# TC80_VXX register map
Vendor: Geneal MCU Ltd.; Series: ARMCM0; File version: 1.2
CPU: CM0 r0p0, little endian, no MPU, no FPU, 2 interrupt priority bits
Registers are 32-bit, read-write, reset 0x0 unless marked. A register's access mark holds for its fields unless they carry their own. Offsets are from the block's base; [hi:lo] are bit positions.

## FLASH
Base 0x40008000
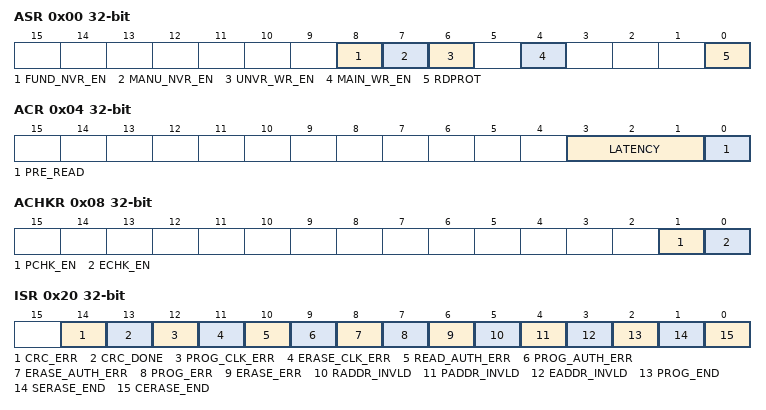
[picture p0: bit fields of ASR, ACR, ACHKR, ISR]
0x00 ASR ro (reset mask 0x3) — Flash access state register
  [8] FUND_NVR_EN — Manu flash write enable
  [7] MANU_NVR_EN — Manu flash write enable
  [6] UNVR_WR_EN — Manu flash write enable
  [4] MAIN_WR_EN — Main flash write enable
  [0] RDPROT — Read protect enable
0x04 ACR — Flash access control register
  [3:1] LATENCY — Flash wait cycle setting
  [0] PRE_READ — Flash pre read enable
0x08 ACHKR — Flash program/erase check enable register
  [1] PCHK_EN — Program check enable
    0=Disable (Program check is disabled); 1=Enable (Program check is enable)
  [0] ECHK_EN — erase check enable
    0=Disable (Erase check is disabled); 1=Enable (Erase check is enable)
0x0C PEKEYR (reset mask 0x3F) — Flash program/erase key register
  [31:0] PEKEY — Program check enable
    0xF0AA1234=Program is enabled; 0xF055ABCD=Sector erase is enable; 0xF0CC5678=Chip erase is enable
0x20 ISR (reset mask 0x67FF) — Flash interrupt flag register
  [14] CRC_ERR — CRC check error flag
  [13] CRC_DONE — CRC check over error flag
  [12] PROG_CLK_ERR — Read clk error flag
  [11] ERASE_CLK_ERR — Erase clk error flag
  [10] READ_AUTH_ERR — Read auth error flag
  [9] PROG_AUTH_ERR — Program auth error flag
  [8] ERASE_AUTH_ERR — Erase auth error flag
  [7] PROG_ERR — Program error flag
  [6] ERASE_ERR — Erase error flag
  [5] RADDR_INVLD — Read invalid address flag
  [4] PADDR_INVLD — Program invalid address flag
  [3] EADDR_INVLD — Erase invalid address flag
  [2] PROG_END — Program done flag
  [1] SERASE_END — Sector erase done flag
  [0] CERASE_END — Chip erase done flag
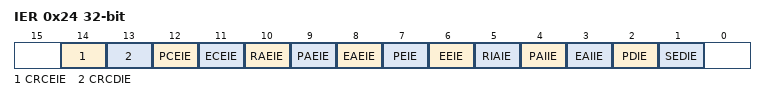
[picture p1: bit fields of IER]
0x24 IER (reset mask 0x67FE) — Flash interrupt enable register
  [all] fields
    0=Disable (Interrupt disabled); 1=Enable (Interrupt is enabled)
  [14] CRCEIE — CRC check error interrupt ennable
  [13] CRCDIE — CRC check done interrupt ennable
  [12] PCEIE — Read auth error interrupt ennable
  [11] ECEIE — Read auth error interrupt ennable
  [10] RAEIE — Read auth error interrupt ennable
  [9] PAEIE — Program auth error interrupt ennable
  [8] EAEIE — Erase auth error interrupt ennable
  [7] PEIE — Program error interrupt ennable
  [6] EEIE — Erase error interrupt ennable
  [5] RIAIE — Read invalid address interrupt ennable
  [4] PAIIE — Program invalid address interrupt ennable
  [3] EAIIE — Erase invalid address interrupt ennable
  [2] PDIE — Program done interrupt ennable
  [1] SEDIE — Sector erase done interrupt ennable
0x30 TKEYR — self config timing register
0x34 TNVS — self config timing nvs register
0x38 TPROG reset 0x1A — self config timing tprog register
  [4:0] TPROG — TPROG PARAMETER
0x3C TADS (reset mask 0xFFFFFFF1A) — self config timing ADS register
  [0] TADS — TPROG PARAMETER
0x40 TADH (reset mask 0xFFFFFFF1A) — self config timing ADH register
  [0] TADH — TPROG PARAMETER
0x44 TPGS reset 0x16 — self config timing ADH register
  [4:0] TPGS — TPROG PARAMETER
0x48 TPGH (reset mask 0xFFFFFFF1A) — self config timing ADH register
  [0] TPGH — TPROG PARAMETER
0x4C TPRCV — Flash tprcv register
  [4:0] TPRCV — TPRCV PARAMETER
0x50 TSRCV — Flash tSrcv register
  [7:0] TSRCV — TSRCV PARAMETER
0x54 TCRCV reset 0x376 — Flash tCrcv register
  [9:0] TCRCV — TCRCV PARAMETER
0x58 TSERASE — Flash tCrcv register
  [14:0] TSERASE — TERASE PARAMETER
0x5C TCERASE — Flash TCERASE register
  [16:0] TCERASE — TERASE PARAMETER
0x60 TRW — Flash TRW register
  [0] TRW — TRW PARAMETER
0xF0 CRCCR wo — Flash CRCCR register
  [0] START — START PARAMETER
0xF4 ICRCAR — Flash ICRCAR register
  [23:9] INIT_ADDR — INIT_ADDR PARAMETER
0xF8 ECRCAR — Flash ECRCAR register
  [23:9] END_ADDR — END_ADDR PARAMETER
0xFC CRCVR — Flash CRCVR register
  [15:0] VAL — VAL PARAMETER
0x100 PKEYR — Flash PKEYR register
0x104 PRGKEYR wo — Flash PRGKEYR register
0x10C NVR_WR_EN wo — Flash NVR_WR_EN register
0x234 MNKEYR wo — Flash MNKEYR register
0x238 FNKEYR wo — Flash FNKEYR register
